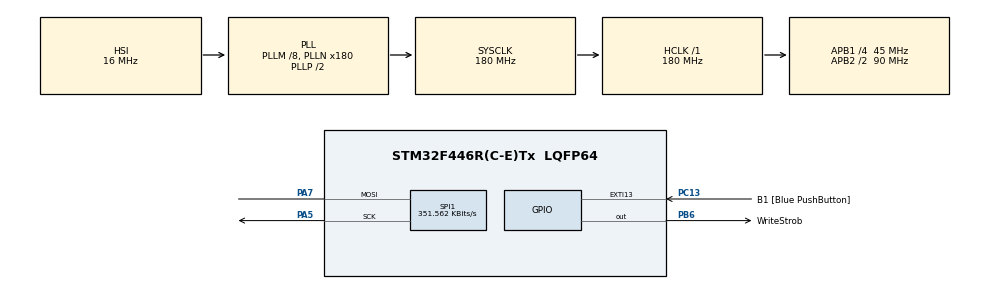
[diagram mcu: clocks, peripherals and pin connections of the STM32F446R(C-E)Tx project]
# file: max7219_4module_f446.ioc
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Mcu.Family=STM32F4
Mcu.Name=STM32F446R(C-E)Tx
Mcu.Package=LQFP64
NVIC.PriorityGroup=NVIC_PRIORITYGROUP_0
PA13.GPIO_Label=TMS
PA13.Mode=Serial_Wire
PA13.Signal=SYS_JTMS-SWDIO
PA14.GPIO_Label=TCK
PA14.Mode=Serial_Wire
PA14.Signal=SYS_JTCK-SWCLK
PA2.GPIO_Label=USART_TX
PA2.Signal=USART2_TX
PA3.GPIO_Label=USART_RX
PA3.Signal=USART2_RX
PA5.Mode=Simplex_Bidirectional_Master
PA5.Signal=SPI1_SCK
PA7.Mode=Simplex_Bidirectional_Master
PA7.Signal=SPI1_MOSI
PB3.Signal=SPI3_SCK
PB4.Signal=SPI3_MISO
PB6.GPIO_Label=WriteStrob
PB6.GPIO_PuPd=GPIO_PULLUP
PB6.GPIO_Speed=GPIO_SPEED_FREQ_LOW
PB6.Signal=GPIO_Output
PC13.GPIO_Label=B1 [Blue PushButton]
PC13.GPIO_ModeDefaultEXTI=GPIO_MODE_IT_FALLING
PC13.Signal=GPXTI13
PC14-OSC32_IN.Mode=LSE-External-Oscillator
PC14-OSC32_IN.Signal=RCC_OSC32_IN
PC15-OSC32_OUT.Mode=LSE-External-Oscillator
PC15-OSC32_OUT.Signal=RCC_OSC32_OUT
PH0-OSC_IN.Mode=HSE-External-Clock-Source
PH0-OSC_IN.Signal=RCC_OSC_IN
PH1-OSC_OUT.Mode=HSE-External-Clock-Source
PH1-OSC_OUT.Signal=RCC_OSC_OUT
ProjectManager.HeapSize=0x200
ProjectManager.StackSize=0x400
ProjectManager.TargetToolchain=SW4STM32
RCC.48MHZClocksFreq_Value=84000000
RCC.AHBFreq_Value=180000000
RCC.APB1CLKDivider=RCC_HCLK_DIV4
RCC.APB1Freq_Value=45000000
RCC.APB1TimFreq_Value=90000000
RCC.APB2CLKDivider=RCC_HCLK_DIV2
RCC.APB2Freq_Value=90000000
RCC.APB2TimFreq_Value=180000000
RCC.CortexFreq_Value=180000000
RCC.FLatency-AdvancedSettings=FLASH_LATENCY_5
RCC.HCLKFreq_Value=180000000
RCC.HSE_VALUE=8000000
RCC.HSI_VALUE=16000000
RCC.PLLM=8
RCC.PLLN=180
RCC.SYSCLKFreq_VALUE=180000000
RCC.SYSCLKSource=RCC_SYSCLKSOURCE_PLLCLK
RCC.USBFreq_Value=180000000
RCC.VCOOutputFreq_Value=360000000
SPI1.BaudRatePrescaler=SPI_BAUDRATEPRESCALER_256
SPI1.CalculateBaudRate=351.562 KBits/s
SPI1.Direction=SPI_DIRECTION_1LINE
SPI1.Mode=SPI_MODE_MASTER
SPI1.VirtualType=VM_MASTER
board=NUCLEO-F446RE

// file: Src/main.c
/* USER CODE BEGIN Header */
/**
  ******************************************************************************
  * @file           : main.c
  * @brief          : Main program body
  ******************************************************************************
  * @attention
  *
  * <h2><center>&copy; Copyright (c) 2019 STMicroelectronics.
  * All rights reserved.</center></h2>
  *
  * This software component is licensed by ST under BSD 3-Clause license,
  * the "License"; You may not use this file except in compliance with the
  * License. You may obtain a copy of the License at:
  *                        opensource.org/licenses/BSD-3-Clause
  *
  ******************************************************************************
  */
/* USER CODE END Header */

#include "main.h"
#include "spi.h"
#include "gpio.h"

/* USER CODE BEGIN Includes */

#include "max7219_4x_dot_sm.h"

/* USER CODE END Includes */

void SystemClock_Config(void);

int main(void)
{
  /* USER CODE BEGIN 1 */

	uint32_t time_u32 = 3657;

  /* USER CODE END 1 */

  /* MCU Configuration--------------------------------------------------------*/

  /* Reset of all peripherals, Initializes the Flash interface and the Systick. */
  HAL_Init();

  /* Configure the system clock */
  SystemClock_Config();

  /* Initialize all configured peripherals */
  MX_GPIO_Init();
  MX_SPI1_Init();
  /* USER CODE BEGIN 2 */

	max7219_struct h1_max7219 =
	{
		.spi		= &hspi1,
		.cs_port	= WriteStrob_GPIO_Port,
		.cs_pin		= WriteStrob_Pin
	};

	max7219_init(&h1_max7219, NoDecode, Intensity_3, DisplayDigit_0_7, NormalOperation);

  /* USER CODE END 2 */

  /* Infinite loop */
  /* USER CODE BEGIN WHILE */
  while (1)
  {
	 time_u32++;
	 max7219_show_time(&h1_max7219, time_u32/100, time_u32%100);
	 HAL_Delay(300);
    /* USER CODE END WHILE */

  }
}

void SystemClock_Config(void)
{
  RCC_OscInitTypeDef RCC_OscInitStruct = {0};
  RCC_ClkInitTypeDef RCC_ClkInitStruct = {0};

  /** Configure the main internal regulator output voltage
  */
  __HAL_RCC_PWR_CLK_ENABLE();
  __HAL_PWR_VOLTAGESCALING_CONFIG(PWR_REGULATOR_VOLTAGE_SCALE1);
  /** Initializes the CPU, AHB and APB busses clocks
  */
  RCC_OscInitStruct.OscillatorType = RCC_OSCILLATORTYPE_HSI;
  RCC_OscInitStruct.HSIState = RCC_HSI_ON;
  RCC_OscInitStruct.HSICalibrationValue = RCC_HSICALIBRATION_DEFAULT;
  RCC_OscInitStruct.PLL.PLLState = RCC_PLL_ON;
  RCC_OscInitStruct.PLL.PLLSource = RCC_PLLSOURCE_HSI;
  RCC_OscInitStruct.PLL.PLLM = 8;
  RCC_OscInitStruct.PLL.PLLN = 180;
  RCC_OscInitStruct.PLL.PLLP = RCC_PLLP_DIV2;
  RCC_OscInitStruct.PLL.PLLQ = 2;
  RCC_OscInitStruct.PLL.PLLR = 2;
  if (HAL_RCC_OscConfig(&RCC_OscInitStruct) != HAL_OK)
  {
    Error_Handler();
  }
  /** Activate the Over-Drive mode
  */
  if (HAL_PWREx_EnableOverDrive() != HAL_OK)
  {
    Error_Handler();
  }
  /** Initializes the CPU, AHB and APB busses clocks
  */
  RCC_ClkInitStruct.ClockType = RCC_CLOCKTYPE_HCLK|RCC_CLOCKTYPE_SYSCLK
                              |RCC_CLOCKTYPE_PCLK1|RCC_CLOCKTYPE_PCLK2;
  RCC_ClkInitStruct.SYSCLKSource = RCC_SYSCLKSOURCE_PLLCLK;
  RCC_ClkInitStruct.AHBCLKDivider = RCC_SYSCLK_DIV1;
  RCC_ClkInitStruct.APB1CLKDivider = RCC_HCLK_DIV4;
  RCC_ClkInitStruct.APB2CLKDivider = RCC_HCLK_DIV2;

  if (HAL_RCC_ClockConfig(&RCC_ClkInitStruct, FLASH_LATENCY_5) != HAL_OK)
  {
    Error_Handler();
  }
}

void Error_Handler(void)
{
}

/************************ (C) COPYRIGHT STMicroelectronics *****END OF FILE****/
